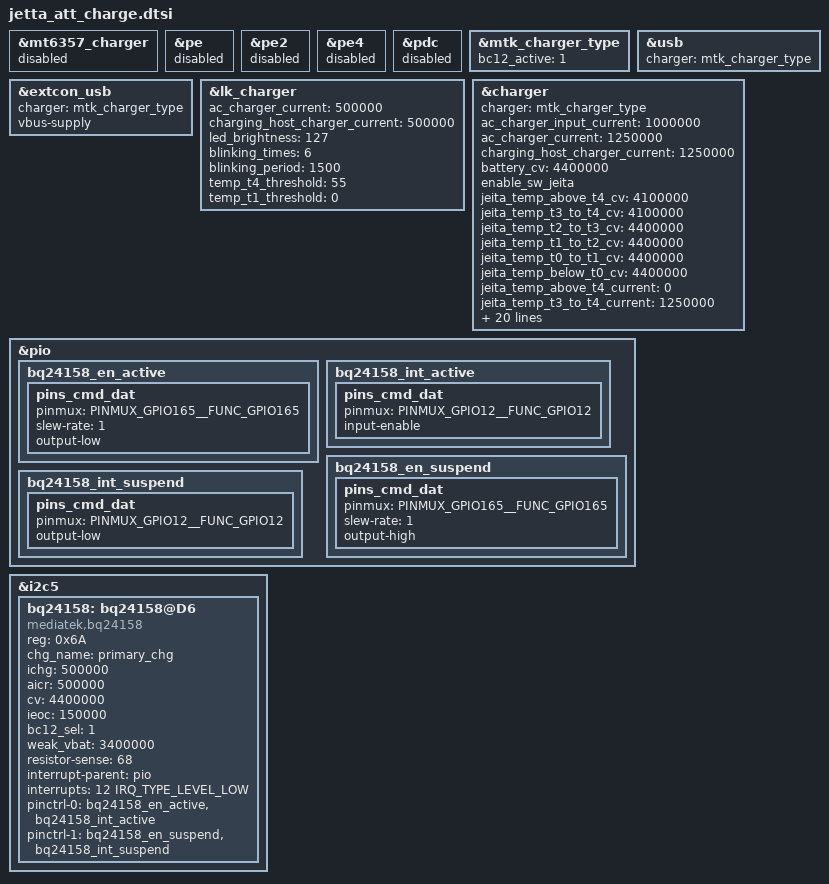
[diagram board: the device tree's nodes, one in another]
// SPDX-License-Identifier: GPL-2.0+
 &mt6357_charger {
	status = "disabled";
 };

&pe {
	status = "disabled";
};

&pe2 {
	status = "disabled";
};

&pe4 {
	status = "disabled";
};

&pdc {
	status = "disabled";
};

&mtk_charger_type {
	bc12_active = <1>;
};

&usb {
	charger = <&mtk_charger_type>;
};

&extcon_usb {
	charger = <&mtk_charger_type>;
	vbus-supply;
};

&lk_charger {
	/delete-property/enable_pe_plus;
	/delete-property/enable_pd20_reset;
	/delete-property/power_path_support;

	ac_charger_current = <500000>;
	charging_host_charger_current = <500000>;
	led_brightness = <127>;
	blinking_times = <6>;
	blinking_period = <1500>;
	temp_t4_threshold = <55>;
	temp_t1_threshold = <0>;
};

&charger {
	charger = <&mtk_charger_type>;
	/delete-property/enable_pe_plus;
	/delete-property/enable_pe_2;
	/delete-property/enable_pe_3;
	/delete-property/enable_pe_4;
	/delete-property/enable_type_c;
	/delete-property/power_path_support;
	/delete-property/enable_min_charge_temp;
	/delete-property/enable_dynamic_mivr;
	ac_charger_input_current = <1000000>;
	ac_charger_current = <1250000>;
	charging_host_charger_current = <1250000>;
	battery_cv = <4400000>;
	enable_sw_jeita;
	/* sw jeita */
	jeita_temp_above_t4_cv = <4100000>;
	jeita_temp_t3_to_t4_cv = <4100000>;
	jeita_temp_t2_to_t3_cv = <4400000>;
	jeita_temp_t1_to_t2_cv = <4400000>;
	jeita_temp_t0_to_t1_cv = <4400000>;
	jeita_temp_below_t0_cv = <4400000>;
	jeita_temp_above_t4_current = <0>;
	jeita_temp_t3_to_t4_current = <1250000>;
	jeita_temp_t2_to_t3_current = <1250000>;
	jeita_temp_t1_to_t2_current = <550000>;
	jeita_temp_t0_to_t1_current = <550000>;
	jeita_temp_below_t0_current = <0>;

	temp_t4_thres = <53>;
	temp_t4_thres_minus_x_degree = <51>;
	temp_t3_thres = <42>;
	temp_t3_thres_minus_x_degree = <43>;
	temp_t2_thres = <11>;
	temp_t2_thres_plus_x_degree = <10>;
	temp_t1_thres = <6>;
	temp_t1_thres_plus_x_degree = <5>;
	temp_t0_thres = <2>;
	temp_t0_thres_plus_x_degree = <1>;
	temp_neg_10_thres = <2>;

	enable_min_charge_temp;
	min_charge_temp = <1>;
	min_charge_temp_plus_x_degree = <2>;
	max_charge_temp = <53>;
	max_charge_temp_minus_x_degree = <51>;
};

&pio {
	bq24158_en_active:bq24158_en_active {
		pins_cmd_dat {
			pinmux = <PINMUX_GPIO165__FUNC_GPIO165>;
			slew-rate = <1>;
			output-low;
		};
	};
	bq24158_int_active: bq24158_int_active {
		pins_cmd_dat {
			pinmux = <PINMUX_GPIO12__FUNC_GPIO12>;
			input-enable;
		};
	};
	bq24158_en_suspend:bq24158_en_suspend {
		pins_cmd_dat {
			pinmux = <PINMUX_GPIO165__FUNC_GPIO165>;
			slew-rate = <1>;
			output-high;
		};
	};
	bq24158_int_suspend: bq24158_int_suspend {
		pins_cmd_dat {
			pinmux = <PINMUX_GPIO12__FUNC_GPIO12>;
			output-low;
		};
	};
};

&i2c5 {
	bq24158:bq24158@D6{
		compatible = "mediatek,bq24158";
		reg = <0x6A>;
		chg_name = "primary_chg";
		ichg = <500000>;		/* uA */
		aicr = <500000>;		/* uA */
		cv = <4400000>;			/* uA */
		ieoc = <150000>;		/* uA */
		bc12_sel = <1>;
		weak_vbat = <3400000>;
		resistor-sense = <68>;
		interrupt-parent = <&pio>;
		interrupts = <12 IRQ_TYPE_LEVEL_LOW>;
		interrupt-names = "bq24158_chg_stat_irq";
		pinctrl-names = "bq24158_active", "bq24158_suspend";
		pinctrl-0 = <&bq24158_en_active &bq24158_int_active>;
		pinctrl-1 = <&bq24158_en_suspend &bq24158_int_suspend>;
		status = "okay";
	};
};
